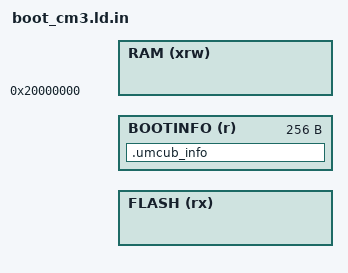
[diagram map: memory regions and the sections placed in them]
/*
 * umcub bootloader, STM32F1. Preprocessed with umcub_cfg.h.
 */
#include "umcub_cfg.h"

MEMORY
{
  FLASH (rx)   : ORIGIN = UMCUB_CFG_BOOT_ADDR, LENGTH = UMCUB_CFG_BOOT_INFO_ADDR - UMCUB_CFG_BOOT_ADDR
  BOOTINFO (r) : ORIGIN = UMCUB_CFG_BOOT_INFO_ADDR, LENGTH = 256
  RAM   (xrw)  : ORIGIN = 0x20000000, LENGTH = UMCUB_CFG_SHARED_RAM_ADDR - 0x20000000   /* handoff above */
}

_Min_Heap_Size  = 0;
_Min_Stack_Size = 0x1000;   /* measured peak 2.9 KiB: SMP upload of an encrypted image (tools/hw/stack_usage.py) */

_estack_main = ORIGIN(RAM) + LENGTH(RAM);
_estack = _estack_main;

SECTIONS
{
  .umcub_info :
  {
    KEEP(*(.umcub_info))
  } >BOOTINFO
}

#include "../../common/cortexm_sections.ld.inc"
